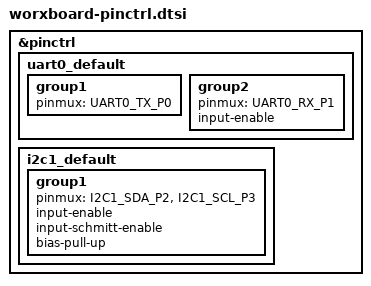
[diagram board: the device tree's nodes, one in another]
/* SPDX-License-Identifier: MIT */
#include <zephyr/dt-bindings/pinctrl/rpi-pico-rp2040-pinctrl.h>

&pinctrl {
    /* Wired split over TRRS: GP0 = UART0 TX, GP1 = UART0 RX (cross TX/RX on the PCB) */
    uart0_default: uart0_default {
        group1 {
            pinmux = <UART0_TX_P0>;
        };
        group2 {
            pinmux = <UART0_RX_P1>;
            input-enable;
        };
    };

    /* SSD1306 OLED on I2C1: GP2 = SDA, GP3 = SCL. R14/R15 (4.7k) pull up on the PCB; the
     * internal pull-ups are a backup only. */
    i2c1_default: i2c1_default {
        group1 {
            pinmux = <I2C1_SDA_P2>, <I2C1_SCL_P3>;
            input-enable;
            input-schmitt-enable;
            bias-pull-up;
        };
    };
};
